# FSI_RX_FSI_RX_CFG_50290000h register map
Vendor: Texas Instruments
Peripheral module from a debugger description file (folder AM263X).
Registers are 16-bit, read-write, reset 0x0 unless marked. A register's access mark holds for its fields unless they carry their own. Offsets are as the file gives them; lines under a group give offsets from that group; [hi:lo] are bit positions; {n}, {i} and the like mark numbered series; 'fields as' and 'values as' point back to an identical list; <NAME> marks a mode.

## FSI_RX_CFG (part 1 of 2)
0x28 FSI_RX_CFG_RX_FRAME_WD_CNT 32-bit ro — Receive frame watchdog current count.
  [31:0] FRAME_WD_CNT — Frame Watchdog Counter Value This is the 32-bit read-only register which shows the current value of the frame watchdog counter. This counter is reset to 0 in a variety of ways: A write to FRME_WD_CNT_RST, a match with FRAME_WD_REF, or the reception of a successful data frame.
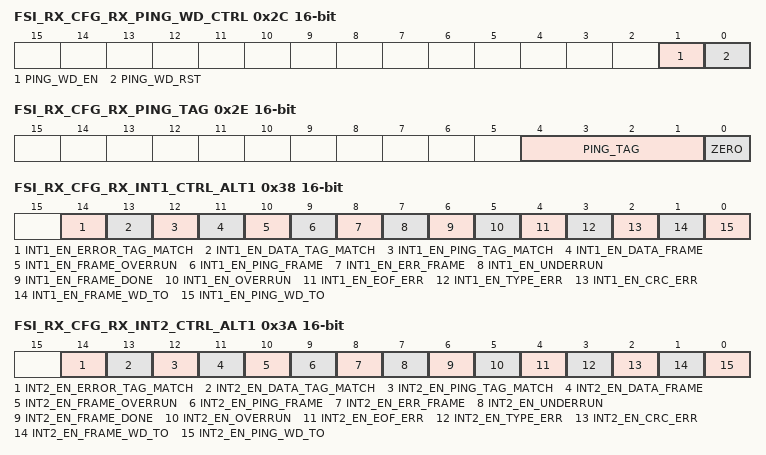
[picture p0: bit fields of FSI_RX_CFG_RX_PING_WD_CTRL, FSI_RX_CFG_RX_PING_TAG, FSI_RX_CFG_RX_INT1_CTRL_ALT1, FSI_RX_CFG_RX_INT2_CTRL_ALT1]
0x2C FSI_RX_CFG_RX_PING_WD_CTRL — Receive ping watchdog control register.
  [1] PING_WD_EN — Ping Watchdog Counter Enable bit This bit will enable or disable the ping watchdog counter. The counter [RX_PING_WD_CNT] will begin counting from 0 when it is enabled. When the reference value [RX_PING_WD_REF] is reached, it will generate a ping watchdog timeout event [RX_EVT_STS.PING_WD_TO] and the counter value will reset to 0, and resume counting 0h[R/W] = The ping watchdog counter is disabled and not running. 1h[R/W] = The ping watchdog counter logic is enabled and running.
  [0] PING_WD_RST — Ping Watchdog Counter Reset bit This bit will reset the ping watchdog counter to 0. Writing a 1 to this bit will reset the ping watchdog counter to 0. The counter will stay in reset as long as this bit is set to 1. This bit needs to be cleared to 0 to use the counter 0h[R/W] = Clear the PING_WD_RST. 1h[W] = The ping watchdog counter will be reset to 0.
0x2E FSI_RX_CFG_RX_PING_TAG ro — Receive ping tag register.
  [4:1] PING_TAG — Received Ping Frame Tag This field contains the 4-bit frame tag from the last successfully received ping frame. This is intentionally shifted into bits 4:1 so that the register can be used as a 32-bit address index based on the received tag.
  [0] ZERO — Zero bit This bit will always read as 0. This is intentionally provided to create a 32-bit offset if required. Using the PING_TAG and ZERO bits of this register [bits 4:0], application software can directly index into an array of 32-bit data.
0x30 FSI_RX_CFG_RX_PING_WD_REF 32-bit — Receive ping watchdog counter reference.
  [31:0] PING_WD_REF — Ping Watchdog Counter Reference Value This is the 32-bit reference value for the ping watchdog timeout counter. The counter will count up starting from 0 and continue counting until this value is reached.
0x34 FSI_RX_CFG_RX_PING_WD_CNT 32-bit ro — Receive pingwatchdog current count.
  [31:0] PING_WD_CNT — Ping Watchdog Counter Value This is the 32-bit read-only register which shows the current value of the ping watchdog counter. This counter is reset to 0 in a variety of ways: A write to PING_WD_RST, a match with PING_WD_REF, or the reception of a ping frame.
0x38 FSI_RX_CFG_RX_INT1_CTRL_ALT1 — Receive interrupt control register for RX_INT1.
  [14] INT1_EN_ERROR_TAG_MATCH — Enable Error Frame Received with Tag Match Interrupt to INT1 bit This is an enable register which decides whether an interrupt [RX_INT1] will be generated on the enabled event. 0h[R/W] = This event will not trigger an interrupt on RX_INT1. 1h[R/W] = An error frame received with matching tag will trigger an interrupt on RX_INT1. The event itself will be latched in the corresponding bit in the RX_EVT_STS Register
  [13] INT1_EN_DATA_TAG_MATCH — Enable Data Frame Received with Tag Match Interrupt to INT1 bit This is an enable register which decides whether an interrupt [RX_INT1] will be generated on the enabled event. 0h[R/W] = This event will not trigger an interrupt on RX_INT1. 1h[R/W] = A data frame received with matching tag will trigger an interrupt on RX_INT1. The event itself will be latched in the corresponding bit in the RX_EVT_STS Register
  [12] INT1_EN_PING_TAG_MATCH — Enable Ping Frame Received with Tag Match Interrupt to INT1 bit This is an enable register which decides whether an interrupt [RX_INT1] will be generated on the enabled event. 0h[R/W] = This event will not trigger an interrupt on RX_INT1. 1h[R/W] = A ping frame received with matching tag will trigger an interrupt on RX_INT1. The event itself will be latched in the corresponding bit in the RX_EVT_STS Register
  [11] INT1_EN_DATA_FRAME — Enable Data Frame Received Interrupt to INT1 bit This is an enable register which decides whether an interrupt [RX_INT1] will be generated on the enabled event. 0h[R/W] = This event will not trigger an interrupt on RX_INT1. 1h[R/W] = A data frame received event will trigger an interrupt on RX_INT1. The event itself will be latched in the corresponding bit in the RX_EVT_STS Register
  [10] INT1_EN_FRAME_OVERRUN — Enable Frame Overrun Interrupt to INT1 bit This is an enable register which decides whether an interrupt [RX_INT1] will be generated on the enabled event. 0h[R/W] = This event will not trigger an interrupt on RX_INT1. 1h[R/W] = A frame overrun event will trigger an interrupt on RX_INT1. The event itself will be latched in the corresponding bit in the RX_EVT_STS Register
  [9] INT1_EN_PING_FRAME — Enable Ping Frame Received Interrupt to INT1 bit This is an enable register which decides whether an interrupt [RX_INT1] will be generated on the enabled event. 0h[R/W] = This event will not trigger an interrupt on RX_INT1. 1h[R/W] = A ping frame received event will trigger an interrupt on RX_INT1. The event itself will be latched in the corresponding bit in the RX_EVT_STS Register
  [8] INT1_EN_ERR_FRAME — Enable ERROR Frame Received Interrupt to INT1 bit This is an enable register which decides whether an interrupt [RX_INT1] will be generated on the enabled event. 0h[R/W] = This event will not trigger an interrupt on RX_INT1. 1h[R/W] = A error frame received event will trigger an interrupt on RX_INT1. The event itself will be latched in the corresponding bit in the RX_EVT_STS Register
  [7] INT1_EN_UNDERRUN — Enable Buffer Underrun Interrupt to INT1 bit This is an enable register which decides whether an interrupt [RX_INT1] will be generated on the enabled event. 0h[R/W] = This event will not trigger an interrupt on RX_INT1. 1h[R/W] = A buffer underrun event will trigger an interrupt on RX_INT1. The event itself will be latched in the corresponding bit in the RX_EVT_STS Register
  [6] INT1_EN_FRAME_DONE — Enable Frame Done Interrupt to INT1 bit This is an enable register which decides whether an interrupt [RX_INT1] will be generated on the enabled event. 0h[R/W] = This event will not trigger an interrupt on RX_INT1. 1h[R/W] = A frame done event will trigger an interrupt on RX_INT1. The event itself will be latched in the corresponding bit in the RX_EVT_STS Register
  [5] INT1_EN_OVERRUN — Enable Receive Buffer Overrun Interrupt to INT1 bit This is an enable register which decides whether an interrupt [RX_INT1] will be generated on the enabled event. 0h[R/W] = This event will not trigger an interrupt on RX_INT1. 1h[R/W] = A receive buffer overrun event will trigger an interrupt on RX_INT1. The event itself will be latched in the corresponding bit in the RX_EVT_STS Register
  [4] INT1_EN_EOF_ERR — Enable End-of-Frame Error Interrupt to INT1 bit This is an enable register which decides whether an interrupt [RX_INT1] will be generated on the enabled event. 0h[R/W] = This event will not trigger an interrupt on RX_INT1. 1h[R/W] = An end-of-frame error event will trigger an interrupt on RX_INT1. The event itself will be latched in the corresponding bit in the RX_EVT_STS Register
  [3] INT1_EN_TYPE_ERR — Enable Frame Type Error Interrupt to INT1 bit This is an enable register which decides whether an interrupt [RX_INT1] will be generated on the enabled event. 0h[R/W] = This event will not trigger an interrupt on RX_INT1. 1h[R/W] = A frame type error event will trigger an interrupt on RX_INT1. The event itself will be latched in the corresponding bit in the RX_EVT_STS Register
  [2] INT1_EN_CRC_ERR — Enable CRC Error Interrupt to INT1 bit This is an enable register which decides whether an interrupt [RX_INT1] will be generated on the enabled event. 0h[R/W] = This event will not trigger an interrupt on RX_INT1. 1h[R/W] = A CRC error will trigger an interrupt on RX_INT1. The event itself will be latched in the corresponding bit in the RX_EVT_STS Register
  [1] INT1_EN_FRAME_WD_TO — Enable Frame Watchdog Timeout Interrupt to INT1 bit This is an enable register which decides whether an interrupt [RX_INT1] will be generated on the enabled event. 0h[R/W] = This event will not trigger an interrupt on RX_INT1. 1h[R/W] = A frame watchdog timeout event will trigger an interrupt on RX_INT1. The event itself will be latched in the corresponding bit in the RX_EVT_STS Register
  [0] INT1_EN_PING_WD_TO — Enable Ping Watchdog Timeout Interrupt to INT1 bit This is an enable register which decides whether an interrupt [RX_INT1] will be generated on the enabled event. 0h[R/W] = This event will not trigger an interrupt on RX_INT1. 1h[R/W] = A ping watchdog timeout event will trigger an interrupt on RX_INT1. The event itself will be latched in the corresponding bit in the RX_EVT_STS Register
0x3A FSI_RX_CFG_RX_INT2_CTRL_ALT1 — Receive interrupt control register for RX_INT2.
  [14] INT2_EN_ERROR_TAG_MATCH — Enable Error Frame Received with Tag Match Interrupt to INT2 bit This is an enable register which decides whether an interrupt [RX_INT2] will be generated on the enabled event. 0h[R/W] = This event will not trigger an interrupt on RX_INT2. 1h[R/W] = An error frame received with matching tag will trigger an interrupt on RX_INT2. The event itself will be latched in the corresponding bit in the RX_EVT_STS Register
  [13] INT2_EN_DATA_TAG_MATCH — Enable Data Frame Received with Tag Match Interrupt to INT2 bit This is an enable register which decides whether an interrupt [RX_INT2] will be generated on the enabled event. 0h[R/W] = This event will not trigger an interrupt on RX_INT2. 1h[R/W] = A data frame received with matching tag will trigger an interrupt on RX_INT2. The event itself will be latched in the corresponding bit in the RX_EVT_STS Register
  [12] INT2_EN_PING_TAG_MATCH — Enable Ping Frame Received with Tag Match Interrupt to INT2 bit This is an enable register which decides whether an interrupt [RX_INT2] will be generated on the enabled event. 0h[R/W] = This event will not trigger an interrupt on RX_INT2. 1h[R/W] = A ping frame received with matching tag will trigger an interrupt on RX_INT2. The event itself will be latched in the corresponding bit in the RX_EVT_STS Register
  [11] INT2_EN_DATA_FRAME — Enable Data Frame Received Interrupt to INT2 bit This is an enable register which decides whether an interrupt [RX_INT2] will be generated on the enabled event. 0h[R/W] = This event will not trigger an interrupt on RX_INT2. 1h[R/W] = A data frame received event will trigger an interrupt on RX_INT2. The event itself will be latched in the corresponding bit in the RX_EVT_STS Register
  [10] INT2_EN_FRAME_OVERRUN — Enable Frame Overrun Interrupt to INT2 bit This is an enable register which decides whether an interrupt [RX_INT2] will be generated on the enabled event. 0h[R/W] = This event will not trigger an interrupt on RX_INT2. 1h[R/W] = A frame overrun event will trigger an interrupt on RX_INT2. The event itself will be latched in the corresponding bit in the RX_EVT_STS Register
  [9] INT2_EN_PING_FRAME — Enable Ping Frame Received Interrupt to INT2 bit This is an enable register which decides whether an interrupt [RX_INT2] will be generated on the enabled event. 0h[R/W] = This event will not trigger an interrupt on RX_INT2. 1h[R/W] = A ping frame received event will trigger an interrupt on RX_INT2. The event itself will be latched in the corresponding bit in the RX_EVT_STS Register
  [8] INT2_EN_ERR_FRAME — Enable Error Frame Received Interrupt to INT2 bit This is an enable register which decides whether an interrupt [RX_INT2] will be generated on the enabled event. 0h[R/W] = This event will not trigger an interrupt on RX_INT2. 1h[R/W] = A error frame received event will trigger an interrupt on RX_INT2. The event itself will be latched in the corresponding bit in the RX_EVT_STS Register
  [7] INT2_EN_UNDERRUN — Enable Buffer Underrun Interrupt to INT2 bit This is an enable register which decides whether an interrupt [RX_INT2] will be generated on the enabled event. 0h[R/W] = This event will not trigger an interrupt on RX_INT2. 1h[R/W] = A buffer underrun event will trigger an interrupt on RX_INT2. The event itself will be latched in the corresponding bit in the RX_EVT_STS Register
  [6] INT2_EN_FRAME_DONE — Enable Frame Done Interrupt to INT2 bit This is an enable register which decides whether an interrupt [RX_INT2] will be generated on the enabled event. 0h[R/W] = This event will not trigger an interrupt on RX_INT2. 1h[R/W] = A frame done event will trigger an interrupt on RX_INT2. The event itself will be latched in the corresponding bit in the RX_EVT_STS Register
  [5] INT2_EN_OVERRUN — Enable Buffer Overrun Interrupt to INT2 bit This is an enable register which decides whether an interrupt [RX_INT2] will be generated on the enabled event. 0h[R/W] = This event will not trigger an interrupt on RX_INT2. 1h[R/W] = A buffer overrun event will trigger an interrupt on RX_INT2. The event itself will be latched in the corresponding bit in the RX_EVT_STS Register
  [4] INT2_EN_EOF_ERR — Enable End-of-Frame Error Interrupt to INT2 bit This is an enable register which decides whether an interrupt [RX_INT2] will be generated on the enabled event. 0h[R/W] = This event will not trigger an interrupt on RX_INT2. 1h[R/W] = An end-of-frame error event will trigger an interrupt on RX_INT2. The event itself will be latched in the corresponding bit in the RX_EVT_STS Register
  [3] INT2_EN_TYPE_ERR — Enable Frame Type Error Interrupt to INT2 bit This is an enable register which decides whether an interrupt [RX_INT2] will be generated on the enabled event. 0h[R/W] = This event will not trigger an interrupt on RX_INT2. 1h[R/W] = A frame type error event will trigger an interrupt on RX_INT2. The event itself will be latched in the corresponding bit in the RX_EVT_STS Register
  [2] INT2_EN_CRC_ERR — Enable CRC Error Interrupt to INT2 bit This is an enable register which decides whether an interrupt [RX_INT2] will be generated on the enabled event. 0h[R/W] = This event will not trigger an interrupt on RX_INT2. 1h[R/W] = A CRC error will trigger an interrupt on RX_INT2. The event itself will be latched in the corresponding bit in the RX_EVT_STS Register
  [1] INT2_EN_FRAME_WD_TO — Enable Frame Watchdog Timeout Interrupt to INT2 bit This is an enable register which decides whether an interrupt [RX_INT2] will be generated on the enabled event. 0h[R/W] = This event will not trigger an interrupt on RX_INT2. 1h[R/W] = A frame watchdog timeout event will trigger an interrupt on RX_INT2. The event itself will be latched in the corresponding bit in the RX_EVT_STS Register
  [0] INT2_EN_PING_WD_TO — Enable Ping Watchdog Timeout Interrupt to INT2 bit This is an enable register which decides whether an interrupt [RX_INT2] will be generated on the enabled event. 0h[R/W] = This event will not trigger an interrupt on RX_INT2. 1h[R/W] = A ping watchdog timeout event will trigger an interrupt on RX_INT2. The event itself will be latched in the corresponding bit in the RX_EVT_STS Register
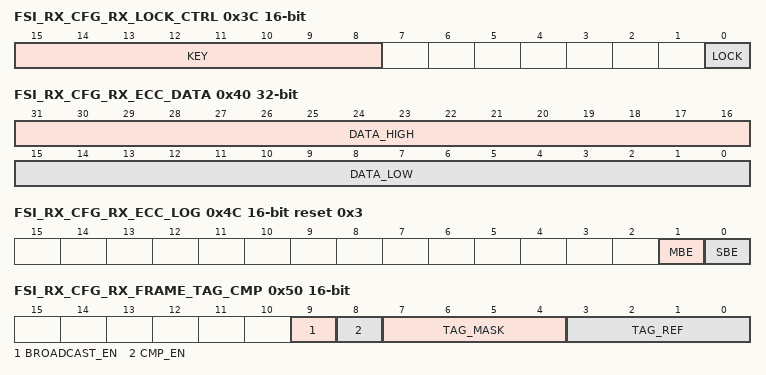
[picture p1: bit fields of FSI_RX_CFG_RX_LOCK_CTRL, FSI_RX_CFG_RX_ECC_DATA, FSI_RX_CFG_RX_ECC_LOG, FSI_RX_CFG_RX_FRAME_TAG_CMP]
0x3C FSI_RX_CFG_RX_LOCK_CTRL access per field — Receive lock control register.
  [15:8] KEY wo — Write Key. In order to write to this register, 0xA5 must be written to this field at the same time. Otherwise, writes are ignored. The key is cleared immediately after Writing, so it must be written again for every change to this register.
  [0] LOCK rw — Control Register Lock Enable bit This bit locks the contents of all the receive control registers that support a lock protection. Once locked, further writes will not take effect until SYSRS unlocks the register. Once set, further writes even to this bit will be ignored. 0h[R/W] = Receive control registers can be modified and are not locked. 1h[R/W] = Receive control registers are locked and cannot be modified until this bit is cleared by SYSRS. Any further writes to this bit are ignored. Note: The KEY field must contatin 0xA5 for any write to this bit to take effect.
0x40 FSI_RX_CFG_RX_ECC_DATA 32-bit — Receive ECC data register.
  [31:16] DATA_HIGH — Upper 16 bits of ECC Data Writing to this bitfield will cause the ECC logic to compute the ECC[SEC-DED] the entire 32-bit register and update TX_ECC_VAL register with the results. Software should write to these 16 bits of the register in a 32-bit write when needing to compute ECC for 32-bits for the full TX_ECC_DATA register.
  [15:0] DATA_LOW — Lower 16 bits of ECC Data Writing to this bitfield will cause the ECC logic to compute the ECC[SEC-DED] for these 16 bits and update the TX_ECC_VAL register with the results. Software should write to these register bits as a 16-bit write when needing to compute ECC for 16-bits.
0x44 FSI_RX_CFG_RX_ECC_VAL — Receive ECC value register.
  [6:0] ECC_VAL — ECC Value for SEC-DED check This field contains the ECC value to be used for SEC-DED either for 16-bit or 32-bit data in the RX_ECC_DATA register.
0x48 FSI_RX_CFG_RX_ECC_SEC_DATA 32-bit ro — Receive ECC corrected data register.
  [31:0] SEC_DATA — ECC Single Error Corrected Data The ECC corrected data will be available in this register. This value is valid only when there are no bit errors, or a single bit error was detected. Otherwise, the contents of this register are invalid and should not be used.
0x4C FSI_RX_CFG_RX_ECC_LOG ro reset 0x3 — Receive ECC log and status register.
  [1] MBE — Multiple Bit Errors Detected This bit indicates the occurrence of multiple bit errors.The data is corrupted and cannot be corrected. If this bit is set, the data present in RX_ECC_SEC_DATA is invalid and should not be used. 0h[R] Multiple Bit Errors were not detected. Check the SBE bit for single bit errors. 1h[R] Multiple Bit Errors were detected. The data is not able to be corrected. The value present in RX_ECC_SEC_DATA is invalid and should not be used.
  [0] SBE — Single Bit Error Detected This bit indicates the occurrence of a single bit error in the data. The data is autocorrected and placed into the RX_ECC_SEC_DATA register. This bit is valid only if MBE is 0. 0h[R] No bit errors were detected. The value in RX_ECC_SEC_DATA is correct. 1h[R] A single bit error was detected and corrected. The corrected data is present in RX_ECC_SEC_DATA.
0x50 FSI_RX_CFG_RX_FRAME_TAG_CMP — Receive frame tag compare register.
  [9] BROADCAST_EN — Broadcast Enable bit This will enable the reception of a ping frame broadcast. When this bit is set, bit 3 of the received tag will be treated as a broadcast notification. If bit 3 of the received tag is set to 1, a ping tag match event will be triggered regardless of the. A match caused by the comparison of TAG_MASK and TAG_REF will still be considered a match and the frame tag match event will be triggered as normal This bit only takes effect only if CMP_EN is set to 1. 0h[R/W] Broadcast frame match disabled. 1h[R/W] Broadcast frame match enabled.
  [8] CMP_EN — Frame Tag Compare Enable bit Set this bit to enable the comparison of an incoming frame tag and the value stored in the frame tag reference. A match caused by the comparison of TAG_MASK, TAG_REF, and the incoming frame tag will trigger the apprpriate frame tag match event. 0h[R/W] Frame tag comparison is disabled. 1h[R/W] Frame tag comparison is enabled.
  [7:4] TAG_MASK — Frame Tag Mask Any bit position in this register set to 0 will be used in the comparison of the incoming frame tag and the value stored in TAG_REF. A bit position set to 1 will be ignored in the tag comparison. This mask value is used only for non-ping frames.
  [3:0] TAG_REF — Frame Tag Reference The reference tag to check against when comparing the TAG_MASK and the incoming frame tag. This reference value is used only for non-ping frames.
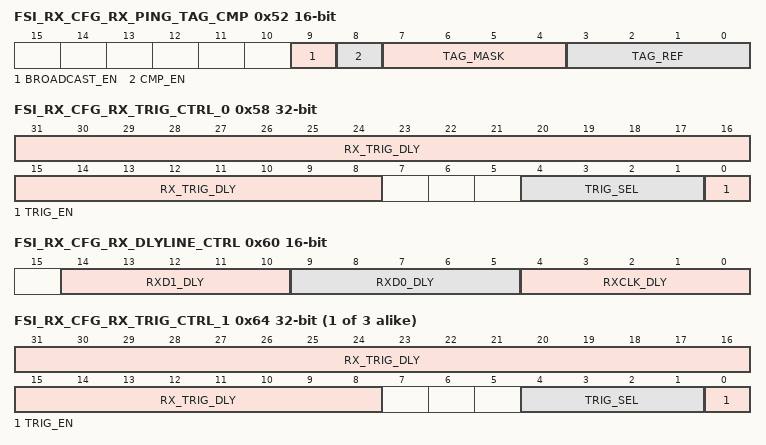
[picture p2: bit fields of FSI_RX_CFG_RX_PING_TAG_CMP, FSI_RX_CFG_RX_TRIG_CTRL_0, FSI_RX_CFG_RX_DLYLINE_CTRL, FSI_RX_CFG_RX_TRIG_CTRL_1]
0x52 FSI_RX_CFG_RX_PING_TAG_CMP — Receive ping tag compare register.
  [9] BROADCAST_EN — Broadcast Enable bit This will enable the reception of a ping frame broadcast. When this bit is set, bit 3 of the received tag will be treated as a broadcast notification. If bit 3 of the received tag is set to 1, a ping tag match event will be triggered regardless of the. A match caused by the comparison of TAG_MASK and TAG_REF will still be considered a match and the ping tag match event will be triggered as normal This bit only takes effect only if CMP_EN is set to 1. 0h[R/W] Broadcast frame match disabled. 1h[R/W] Broadcast frame match enabled.
  [8] CMP_EN — Ping Tag Compare Enable bit Set this bit to enable the comparison of an incoming ping tag and the value stored in the ping tag reference. A match caused by the comparison of TAG_MASK, TAG_REF, and the incoming ping tag will trigger a ping frame tag match event. 0h[R/W] Ping tag comparison is disabled. 1h[R/W] Ping tag comparison is enabled.
  [7:4] TAG_MASK — Ping Tag Mask Any bit position in this register set to 0 will be used in the comparison of the incoming ping frame tag and the value stored in TAG_REF. A bit position set to 1 will be ignored in the tag comparison. This mask value is used only for ping frames.
  [3:0] TAG_REF — Ping Tag Reference The reference tag to check against when comparing the TAG_MASK and the incoming ping tag. This reference value is used only for ping frames.
0x58 FSI_RX_CFG_RX_TRIG_CTRL_0 32-bit — Receive Trigger Control register 0
  [31:8] RX_TRIG_DLY — This is the 24 bit count of the trigger delay in SYSCLK cycles. If enabled, the Trigger-1 output of the trigger module will generate a 3 SYSCLK wide trigger pulse after the selected input trigger source sees a rising edge with a delay defined by this 24-bt value.
  [4:1] TRIG_SEL — This is the mux Select Value which selects which of the inputs will be used as the trigger source.
  [0] TRIG_EN — This is the enable for the RX output trigger generation. The output triggers will be generated only if this bit is set to 1. If this bit is 0, then no trigger will be generated by this module.
0x5C FSI_RX_CFG_RX_TRIG_WIDTH_0 32-bit — Receive Trigger Wdith register 0
  [15:0] RX_TRIG_WIDTH — This register decides the width[in SYSCLK cycles] of wide pulse output of the RX trigger module.
0x60 FSI_RX_CFG_RX_DLYLINE_CTRL — Receive delay line control register.
  [14:10] RXD1_DLY — Delay Line Tap Select for RXD1 This bitfield selects the number of delay elements inserted into the RXD1 path from the pin boundary to the receiver core. 0h[R/W] Zero delay elements are included in the RXD1 path. RXD1 is taken directly from the pin. 1h[R/W] One delay element is included in the RXD1 path. 2h[R/W] Two delay elements are included in the RXD1 path. ... 1Fh [R/W] 31 delay elements are included in the RXD1 path, the maximum.
  [9:5] RXD0_DLY — Delay Line Tap Select for RXD0 This bitfield selects the number of delay elements inserted into the RXD0 path from the pin boundary to the receiver core. 0h[R/W] Zero delay elements are included in the RXD0 path. RXD0 is taken directly from the pin. 1h[R/W] One delay element is included in the RXD0 path. 2h[R/W] Two delay elements are included in the RXD0 path. ... 1Fh [R/W] 31 delay elements are included in the RXD0 path, the maximum.
  [4:0] RXCLK_DLY — Delay Line Tap Select for RXCLK This bitfield selects the number of delay elements inserted into the RXCLK path from the pin boundary to the receiver core. 0h[R/W] Zero delay elements are included in the RXCLK path. RXCLK is taken directly from the pin. 1h[R/W] One delay element is included in the RXCLK path. 2h[R/W] Two delay elements are included in the RXCLK path. ... 1Fh [R/W] 31 delay elements are included in the RXCLK path, the maximum.
{0x60+4i} FSI_RX_CFG_RX_TRIG_CTRL_{i} 32-bit (i=1..3) — Receive Trigger Control register {i}
  fields as FSI_RX_CFG_RX_TRIG_CTRL_0
0x70 FSI_RX_CFG_RX_VIS_1 32-bit ro — Receive debug visibility register 1
  [3] RX_CORE_STS — Receiver Core Status bit This bit indicates the status of the receiver core. If this bit is set, the receiver should undergo a reset and subsequent resynchronization with the transmitter. This bit will be always be set when the receiver has detected and end of frame error or a frame type error. This bit can also be set if the receiver becomes corrupted due to noise on the signal lines. If the receiver has experienced a ping watchdog or frame watchdog timeout, this bit should be read to determine if the cause was due to a corrupt transaction, thus putting the receiver core into an unrecoverable state. Only a soft reset will reset the recevier core and thus reset this bit. 0h[R] The receiver core is operating normally. 1h[R] The receiver core has entered into an error state and should be reset.
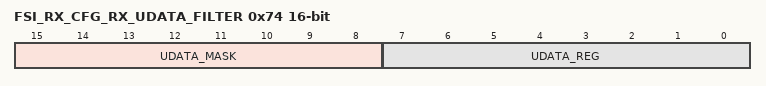
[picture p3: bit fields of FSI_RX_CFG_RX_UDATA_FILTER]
0x74 FSI_RX_CFG_RX_UDATA_FILTER — Receive User Data Filter Control register.
  [15:8] UDATA_MASK — Bit Mask to be used for comparing the USERDATA field when filtering is enabled. Every bit that is '1' in this register will be masked for comparison. If a bit position is '1', then it will be considered a successful match for that bit position.
  [7:0] UDATA_REG — Reference to be used for comparing the USERDATA field when filtering is enabled.
0x80 FSI_RX_CFG_RX_BUF_BASE_j ro — Base address for receive data buffer.
  [15:0] BASE_ADDRESS — Receive Data Buffer Base Address This is the base address of the 16-word data buffer used by the receiver.
